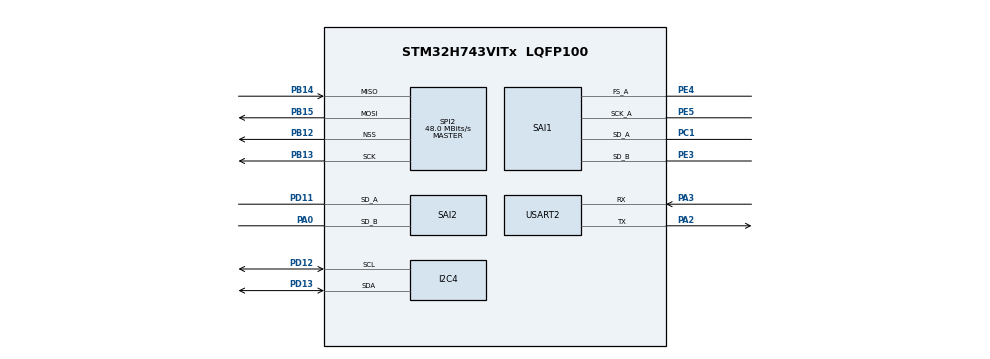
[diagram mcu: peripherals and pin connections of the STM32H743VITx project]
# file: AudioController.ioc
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CORTEX_M7.AccessPermission-Cortex_Memory_Protection_Unit_Region0_Settings=MPU_REGION_FULL_ACCESS
CORTEX_M7.BaseAddress-Cortex_Memory_Protection_Unit_Region0_Settings=0x24000000
CORTEX_M7.CPU_DCache=Enabled
CORTEX_M7.CPU_ICache=Enabled
CORTEX_M7.DisableExec-Cortex_Memory_Protection_Unit_Region0_Settings=MPU_INSTRUCTION_ACCESS_DISABLE
CORTEX_M7.Enable-Cortex_Memory_Protection_Unit_Region0_Settings=MPU_REGION_ENABLE
CORTEX_M7.IsBufferable-Cortex_Memory_Protection_Unit_Region0_Settings=MPU_ACCESS_BUFFERABLE
CORTEX_M7.IsShareable-Cortex_Memory_Protection_Unit_Region0_Settings=MPU_ACCESS_SHAREABLE
CORTEX_M7.MPU_Control=MPU_PRIVILEGED_DEFAULT
CORTEX_M7.Size-Cortex_Memory_Protection_Unit_Region0_Settings=MPU_REGION_SIZE_256KB
Dma.Request0=SAI2_A
Dma.Request1=SAI2_B
Dma.Request2=SAI1_A
Dma.Request3=SAI1_B
Dma.Request4=USART2_RX
Dma.Request5=USART2_TX
Dma.Request6=SPI2_RX
Dma.Request7=SPI2_TX
Dma.SAI1_A.2.Direction=DMA_PERIPH_TO_MEMORY
Dma.SAI1_A.2.EventEnable=DISABLE
Dma.SAI1_A.2.FIFOMode=DMA_FIFOMODE_DISABLE
Dma.SAI1_A.2.Instance=DMA1_Stream2
Dma.SAI1_A.2.MemDataAlignment=DMA_MDATAALIGN_HALFWORD
Dma.SAI1_A.2.MemInc=DMA_MINC_ENABLE
Dma.SAI1_A.2.Mode=DMA_CIRCULAR
Dma.SAI1_A.2.PeriphDataAlignment=DMA_PDATAALIGN_HALFWORD
Dma.SAI1_A.2.PeriphInc=DMA_PINC_DISABLE
Dma.SAI1_A.2.Polarity=HAL_DMAMUX_REQ_GEN_RISING
Dma.SAI1_A.2.Priority=DMA_PRIORITY_MEDIUM
Dma.SAI1_A.2.RequestNumber=1
Dma.SAI1_A.2.SignalID=NONE
Dma.SAI1_A.2.SyncEnable=DISABLE
Dma.SAI1_A.2.SyncPolarity=HAL_DMAMUX_SYNC_NO_EVENT
Dma.SAI1_A.2.SyncRequestNumber=1
Dma.SAI1_A.2.SyncSignalID=NONE
Dma.SAI1_B.3.Direction=DMA_MEMORY_TO_PERIPH
Dma.SAI1_B.3.EventEnable=DISABLE
Dma.SAI1_B.3.FIFOMode=DMA_FIFOMODE_DISABLE
Dma.SAI1_B.3.Instance=DMA1_Stream3
Dma.SAI1_B.3.MemDataAlignment=DMA_MDATAALIGN_HALFWORD
Dma.SAI1_B.3.MemInc=DMA_MINC_ENABLE
Dma.SAI1_B.3.Mode=DMA_CIRCULAR
Dma.SAI1_B.3.PeriphDataAlignment=DMA_PDATAALIGN_HALFWORD
Dma.SAI1_B.3.PeriphInc=DMA_PINC_DISABLE
Dma.SAI1_B.3.Polarity=HAL_DMAMUX_REQ_GEN_RISING
Dma.SAI1_B.3.Priority=DMA_PRIORITY_MEDIUM
Dma.SAI1_B.3.RequestNumber=1
Dma.SAI1_B.3.SignalID=NONE
Dma.SAI1_B.3.SyncEnable=DISABLE
Dma.SAI1_B.3.SyncPolarity=HAL_DMAMUX_SYNC_NO_EVENT
Dma.SAI1_B.3.SyncRequestNumber=1
Dma.SAI1_B.3.SyncSignalID=NONE
Dma.SAI2_A.0.Direction=DMA_PERIPH_TO_MEMORY
Dma.SAI2_A.0.EventEnable=DISABLE
Dma.SAI2_A.0.FIFOMode=DMA_FIFOMODE_DISABLE
Dma.SAI2_A.0.Instance=DMA1_Stream0
Dma.SAI2_A.0.MemDataAlignment=DMA_MDATAALIGN_HALFWORD
Dma.SAI2_A.0.MemInc=DMA_MINC_ENABLE
Dma.SAI2_A.0.Mode=DMA_CIRCULAR
Dma.SAI2_A.0.PeriphDataAlignment=DMA_PDATAALIGN_HALFWORD
Dma.SAI2_A.0.PeriphInc=DMA_PINC_DISABLE
Dma.SAI2_A.0.Polarity=HAL_DMAMUX_REQ_GEN_RISING
Dma.SAI2_A.0.Priority=DMA_PRIORITY_MEDIUM
Dma.SAI2_A.0.RequestNumber=1
Dma.SAI2_A.0.SignalID=NONE
Dma.SAI2_A.0.SyncEnable=DISABLE
Dma.SAI2_A.0.SyncPolarity=HAL_DMAMUX_SYNC_NO_EVENT
Dma.SAI2_A.0.SyncRequestNumber=1
Dma.SAI2_A.0.SyncSignalID=NONE
Dma.SAI2_B.1.Direction=DMA_MEMORY_TO_PERIPH
Dma.SAI2_B.1.EventEnable=DISABLE
Dma.SAI2_B.1.FIFOMode=DMA_FIFOMODE_DISABLE
Dma.SAI2_B.1.Instance=DMA1_Stream1
Dma.SAI2_B.1.MemDataAlignment=DMA_MDATAALIGN_HALFWORD
Dma.SAI2_B.1.MemInc=DMA_MINC_ENABLE
Dma.SAI2_B.1.Mode=DMA_CIRCULAR
Dma.SAI2_B.1.PeriphDataAlignment=DMA_PDATAALIGN_HALFWORD
Dma.SAI2_B.1.PeriphInc=DMA_PINC_DISABLE
Dma.SAI2_B.1.Polarity=HAL_DMAMUX_REQ_GEN_RISING
Dma.SAI2_B.1.Priority=DMA_PRIORITY_MEDIUM
Dma.SAI2_B.1.RequestNumber=1
Dma.SAI2_B.1.SignalID=NONE
Dma.SAI2_B.1.SyncEnable=DISABLE
Dma.SAI2_B.1.SyncPolarity=HAL_DMAMUX_SYNC_NO_EVENT
Dma.SAI2_B.1.SyncRequestNumber=1
Dma.SAI2_B.1.SyncSignalID=NONE
Dma.SPI2_RX.6.Direction=DMA_PERIPH_TO_MEMORY
Dma.SPI2_RX.6.EventEnable=DISABLE
Dma.SPI2_RX.6.FIFOMode=DMA_FIFOMODE_DISABLE
Dma.SPI2_RX.6.Instance=DMA1_Stream6
Dma.SPI2_RX.6.MemDataAlignment=DMA_MDATAALIGN_HALFWORD
Dma.SPI2_RX.6.MemInc=DMA_MINC_ENABLE
Dma.SPI2_RX.6.Mode=DMA_NORMAL
Dma.SPI2_RX.6.PeriphDataAlignment=DMA_PDATAALIGN_HALFWORD
Dma.SPI2_RX.6.PeriphInc=DMA_PINC_DISABLE
Dma.SPI2_RX.6.Polarity=HAL_DMAMUX_REQ_GEN_RISING
Dma.SPI2_RX.6.Priority=DMA_PRIORITY_LOW
Dma.SPI2_RX.6.RequestNumber=1
Dma.SPI2_RX.6.SignalID=NONE
Dma.SPI2_RX.6.SyncEnable=DISABLE
Dma.SPI2_RX.6.SyncPolarity=HAL_DMAMUX_SYNC_NO_EVENT
Dma.SPI2_RX.6.SyncRequestNumber=1
Dma.SPI2_RX.6.SyncSignalID=NONE
Dma.SPI2_TX.7.Direction=DMA_MEMORY_TO_PERIPH
Dma.SPI2_TX.7.EventEnable=DISABLE
Dma.SPI2_TX.7.FIFOMode=DMA_FIFOMODE_DISABLE
Dma.SPI2_TX.7.Instance=DMA1_Stream7
Dma.SPI2_TX.7.MemDataAlignment=DMA_MDATAALIGN_HALFWORD
Dma.SPI2_TX.7.MemInc=DMA_MINC_ENABLE
Dma.SPI2_TX.7.Mode=DMA_NORMAL
Dma.SPI2_TX.7.PeriphDataAlignment=DMA_PDATAALIGN_HALFWORD
Dma.SPI2_TX.7.PeriphInc=DMA_PINC_DISABLE
Dma.SPI2_TX.7.Polarity=HAL_DMAMUX_REQ_GEN_RISING
Dma.SPI2_TX.7.Priority=DMA_PRIORITY_LOW
Dma.SPI2_TX.7.RequestNumber=1
Dma.SPI2_TX.7.SignalID=NONE
Dma.SPI2_TX.7.SyncEnable=DISABLE
Dma.SPI2_TX.7.SyncPolarity=HAL_DMAMUX_SYNC_NO_EVENT
Dma.SPI2_TX.7.SyncRequestNumber=1
Dma.SPI2_TX.7.SyncSignalID=NONE
Dma.USART2_RX.4.Direction=DMA_PERIPH_TO_MEMORY
Dma.USART2_RX.4.EventEnable=DISABLE
Dma.USART2_RX.4.FIFOMode=DMA_FIFOMODE_DISABLE
Dma.USART2_RX.4.Instance=DMA1_Stream4
Dma.USART2_RX.4.MemDataAlignment=DMA_MDATAALIGN_BYTE
Dma.USART2_RX.4.MemInc=DMA_MINC_ENABLE
Dma.USART2_RX.4.Mode=DMA_CIRCULAR
Dma.USART2_RX.4.PeriphDataAlignment=DMA_PDATAALIGN_BYTE
Dma.USART2_RX.4.PeriphInc=DMA_PINC_DISABLE
Dma.USART2_RX.4.Polarity=HAL_DMAMUX_REQ_GEN_RISING
Dma.USART2_RX.4.Priority=DMA_PRIORITY_LOW
Dma.USART2_RX.4.RequestNumber=1
Dma.USART2_RX.4.SignalID=NONE
Dma.USART2_RX.4.SyncEnable=DISABLE
Dma.USART2_RX.4.SyncPolarity=HAL_DMAMUX_SYNC_NO_EVENT
Dma.USART2_RX.4.SyncRequestNumber=1
Dma.USART2_RX.4.SyncSignalID=NONE
Dma.USART2_TX.5.Direction=DMA_MEMORY_TO_PERIPH
Dma.USART2_TX.5.EventEnable=DISABLE
Dma.USART2_TX.5.FIFOMode=DMA_FIFOMODE_DISABLE
Dma.USART2_TX.5.Instance=DMA1_Stream5
Dma.USART2_TX.5.MemDataAlignment=DMA_MDATAALIGN_BYTE
Dma.USART2_TX.5.MemInc=DMA_MINC_ENABLE
Dma.USART2_TX.5.Mode=DMA_NORMAL
Dma.USART2_TX.5.PeriphDataAlignment=DMA_PDATAALIGN_BYTE
Dma.USART2_TX.5.PeriphInc=DMA_PINC_DISABLE
Dma.USART2_TX.5.Polarity=HAL_DMAMUX_REQ_GEN_RISING
Dma.USART2_TX.5.Priority=DMA_PRIORITY_LOW
Dma.USART2_TX.5.RequestNumber=1
Dma.USART2_TX.5.SignalID=NONE
Dma.USART2_TX.5.SyncEnable=DISABLE
Dma.USART2_TX.5.SyncPolarity=HAL_DMAMUX_SYNC_NO_EVENT
Dma.USART2_TX.5.SyncRequestNumber=1
Dma.USART2_TX.5.SyncSignalID=NONE
I2C4.Timing=0x00000E14
Mcu.Family=STM32H7
Mcu.Name=STM32H743VITx
Mcu.Package=LQFP100
NVIC.DMA1_Stream0_IRQn=true\:0\:0\:false\:false\:true\:false\:true\:true
NVIC.DMA1_Stream1_IRQn=true\:0\:0\:false\:false\:true\:false\:true\:true
NVIC.DMA1_Stream2_IRQn=true\:0\:0\:false\:false\:true\:false\:true\:true
NVIC.DMA1_Stream3_IRQn=true\:0\:0\:false\:false\:true\:false\:true\:true
NVIC.DMA1_Stream4_IRQn=true\:0\:0\:false\:false\:true\:false\:true\:true
NVIC.DMA1_Stream5_IRQn=true\:0\:0\:false\:false\:true\:false\:true\:true
NVIC.DMA1_Stream6_IRQn=true\:0\:0\:false\:false\:true\:false\:true\:true
NVIC.DMA1_Stream7_IRQn=true\:0\:0\:false\:false\:true\:false\:true\:true
NVIC.PriorityGroup=NVIC_PRIORITYGROUP_4
NVIC.SAI1_IRQn=true\:0\:0\:false\:false\:true\:true\:true\:true
NVIC.SAI2_IRQn=true\:0\:0\:false\:false\:true\:true\:true\:true
NVIC.SPI2_IRQn=true\:0\:0\:false\:false\:true\:true\:true\:true
NVIC.USART2_IRQn=true\:0\:0\:false\:false\:true\:true\:true\:true
PA0.GPIO_Speed=GPIO_SPEED_FREQ_VERY_HIGH
PA0.Mode=SAI_B_SyncSlave
PA0.Signal=SAI2_SD_B
PA13\ (JTMS/SWDIO).Mode=Trace_Asynchronous_SW
PA13\ (JTMS/SWDIO).Signal=DEBUG_JTMS-SWDIO
PA14\ (JTCK/SWCLK).Mode=Trace_Asynchronous_SW
PA14\ (JTCK/SWCLK).Signal=DEBUG_JTCK-SWCLK
PA2.Mode=Asynchronous
PA2.Signal=USART2_TX
PA3.Mode=Asynchronous
PA3.Signal=USART2_RX
PB12.GPIO_Speed=GPIO_SPEED_FREQ_VERY_HIGH
PB12.Mode=NSS_Signal_Hard_Output
PB12.Signal=SPI2_NSS
PB13.GPIO_Speed=GPIO_SPEED_FREQ_VERY_HIGH
PB13.Mode=Full_Duplex_Master
PB13.Signal=SPI2_SCK
PB14.GPIO_Speed=GPIO_SPEED_FREQ_VERY_HIGH
PB14.Mode=Full_Duplex_Master
PB14.Signal=SPI2_MISO
PB15.GPIO_Speed=GPIO_SPEED_FREQ_VERY_HIGH
PB15.Mode=Full_Duplex_Master
PB15.Signal=SPI2_MOSI
PB3\ (JTDO/TRACESWO).Mode=Trace_Asynchronous_SW
PB3\ (JTDO/TRACESWO).Signal=DEBUG_JTDO-SWO
PC1.GPIO_Speed=GPIO_SPEED_FREQ_VERY_HIGH
PC1.Mode=SAI_A_AsyncSlave
PC1.Signal=SAI1_SD_A
PD11.GPIO_Speed=GPIO_SPEED_FREQ_VERY_HIGH
PD11.Mode=SAI_A_SyncSlave
PD11.Signal=SAI2_SD_A
PD12.GPIO_Speed=GPIO_SPEED_FREQ_HIGH
PD12.Mode=I2C
PD12.Signal=I2C4_SCL
PD13.GPIO_Speed=GPIO_SPEED_FREQ_HIGH
PD13.Mode=I2C
PD13.Signal=I2C4_SDA
PE3.GPIO_Speed=GPIO_SPEED_FREQ_VERY_HIGH
PE3.Mode=SAI_B_SyncSlave
PE3.Signal=SAI1_SD_B
PE4.GPIO_Speed=GPIO_SPEED_FREQ_VERY_HIGH
PE4.Mode=SAI_A_AsyncSlave
PE4.Signal=SAI1_FS_A
PE5.GPIO_Speed=GPIO_SPEED_FREQ_VERY_HIGH
PE5.Mode=SAI_A_AsyncSlave
PE5.Signal=SAI1_SCK_A
PH0-OSC_IN\ (PH0).Mode=HSE-External-Oscillator
PH0-OSC_IN\ (PH0).Signal=RCC_OSC_IN
PH1-OSC_OUT\ (PH1).Mode=HSE-External-Oscillator
PH1-OSC_OUT\ (PH1).Signal=RCC_OSC_OUT
ProjectManager.HeapSize=0x1600
ProjectManager.StackSize=0x2400
ProjectManager.TargetToolchain=STM32CubeIDE
RCC.ADCFreq_Value=12288000
RCC.APB1Freq_Value=120000000
RCC.APB2Freq_Value=120000000
RCC.APB3Freq_Value=120000000
RCC.APB4Freq_Value=120000000
RCC.CortexFreq_Value=480000000
RCC.D1PPRE=RCC_APB3_DIV2
RCC.D2PPRE1=RCC_APB1_DIV2
RCC.D2PPRE2=RCC_APB2_DIV2
RCC.D3PPRE=RCC_APB4_DIV2
RCC.DIVM1=3
RCC.DIVM2=5
RCC.DIVM3=8
RCC.DIVN1=120
RCC.DIVN2=64
RCC.DIVN3=96
RCC.DIVP2=25
RCC.DIVP3=3
RCC.DIVQ3=4
RCC.DIVR3=3
RCC.EnbaleCSS=true
RCC.HCLKFreq_Value=240000000
RCC.HPRE=RCC_HCLK_DIV2
RCC.HSE_VALUE=24000000
RCC.I2C4CLockSelection=RCC_I2C4CLKSOURCE_CSI
RCC.PLLSourceVirtual=RCC_PLLSOURCE_HSE
RCC.SAI1CLockSelection=RCC_SAI1CLKSOURCE_PLL2
RCC.SAI23CLockSelection=RCC_SAI23CLKSOURCE_PLL2
RCC.SPI123CLockSelection=RCC_SPI123CLKSOURCE_PLL3
RCC.SYSCLKFreq_VALUE=480000000
RCC.SYSCLKSource=RCC_SYSCLKSOURCE_PLLCLK
RCC.USBFreq_Value=480000000
SAI1.AudioMode-SAI_B_SyncSlave=SAI_MODESLAVE_TX
SAI1.BasicDataSize-SAI_A_AsyncSlave=SAI_PROTOCOL_DATASIZE_16BITEXTENDED
SAI1.BasicDataSize-SAI_B_SyncSlave=SAI_PROTOCOL_DATASIZE_16BITEXTENDED
SAI1.InitProtocol-SAI_A_AsyncSlave=Enable
SAI1.InitProtocol-SAI_B_SyncSlave=Enable
SAI1.Instance-SAI_A_AsyncSlave=SAI$Index_Block_A
SAI1.Instance-SAI_B_SyncSlave=SAI$Index_Block_B
SAI1.SynchroExt=SAI_SYNCEXT_OUTBLOCKA_ENABLE
SAI1.VirtualMode-SAI_A_AsyncSlave=VM_SLAVE
SAI1.VirtualMode-SAI_B_SyncSlave=VM_SLAVE
SAI1.VirtualProtocol-SAI_A_BASIC=VM_BASIC_PROTOCOL
SAI1.VirtualProtocol-SAI_B_BASIC=VM_BASIC_PROTOCOL
SAI2.AudioMode-SAI_B_SyncSlave=SAI_MODESLAVE_TX
SAI2.BasicDataSize-SAI_A_SyncSlave=SAI_PROTOCOL_DATASIZE_16BITEXTENDED
SAI2.BasicDataSize-SAI_B_SyncSlave=SAI_PROTOCOL_DATASIZE_16BITEXTENDED
SAI2.InitProtocol-SAI_A_SyncSlave=Enable
SAI2.InitProtocol-SAI_B_SyncSlave=Enable
SAI2.Instance-SAI_A_SyncSlave=SAI$Index_Block_A
SAI2.Instance-SAI_B_SyncSlave=SAI$Index_Block_B
SAI2.Synchro_A=SAI_SYNCHRONOUS_EXT_SAI1
SAI2.Synchro_B=SAI_SYNCHRONOUS_EXT_SAI1
SAI2.VirtualMode-SAI_A_SyncSlave=VM_SLAVE
SAI2.VirtualMode-SAI_B_SyncSlave=VM_SLAVE
SAI2.VirtualProtocol-SAI_A_BASIC=VM_BASIC_PROTOCOL
SAI2.VirtualProtocol-SAI_B_BASIC=VM_BASIC_PROTOCOL
SPI2.BaudRatePrescaler=SPI_BAUDRATEPRESCALER_2
SPI2.CalculateBaudRate=48.0 MBits/s
SPI2.DataSize=SPI_DATASIZE_16BIT
SPI2.Direction=SPI_DIRECTION_2LINES
SPI2.Mode=SPI_MODE_MASTER
SPI2.VirtualNSS=VM_NSSHARD
SPI2.VirtualType=VM_MASTER
USART2.AutoBaudRateEnableParam=UART_ADVFEATURE_AUTOBAUDRATE_DISABLE
USART2.OverSampling=UART_OVERSAMPLING_16
USART2.Parity=PARITY_NONE
USART2.RXFIFOThreshold=RXFIFO_THRESHOLD_HALFFULL
USART2.RxPinLevelInvertParam=ADVFEATURE_RXINV_DISABLE
USART2.TXFIFOThreshold=TXFIFO_THRESHOLD_HALFFULL
USART2.TxPinLevelInvertParam=ADVFEATURE_TXINV_DISABLE
USART2.VirtualMode-Asynchronous=VM_ASYNC
USART2.WordLength=WORDLENGTH_8B
VP_SAI1_VP_$IpInstance_SAIA_SAI_BASIC.Mode=SAI_A_BASIC
VP_SAI1_VP_$IpInstance_SAIB_SAI_BASIC.Mode=SAI_B_BASIC
VP_SAI1_VP_$IpInstance_SYNCHRO_EXTERNAL.Mode=SynchroExternal
VP_SAI2_VP_$IpInstance_SAIA_SAI_BASIC.Mode=SAI_A_BASIC
VP_SAI2_VP_$IpInstance_SAIB_SAI_BASIC.Mode=SAI_B_BASIC
board=custom

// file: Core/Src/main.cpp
/* USER CODE BEGIN Header */
/**
 ******************************************************************************
 * @file           : main.c
 * @brief          : Main program body
 ******************************************************************************
 * @attention
 *
 * Copyright (c) 2023 STMicroelectronics.
 * All rights reserved.
 *
 * This software is licensed under terms that can be found in the LICENSE file
 * in the root directory of this software component.
 * If no LICENSE file comes with this software, it is provided AS-IS.
 *
 ******************************************************************************
 */
/* USER CODE END Header */
#include "main.h"
#include "dma.h"
#include "i2c.h"
#include "sai.h"
#include "spi.h"
#include "usart.h"
#include "gpio.h"

/* USER CODE BEGIN Includes */
////////////////////////////////////////////////
////// S A I    O R D E R //////////////////////
////////////////////////////////////////////////
////////////////////////////////////////////////
// ramd1_dma - i fixed linker script
//
/////////////////////////////////////////////////
#include "Handy.h"
#include "../../Drivers/HW/wm8731.h"
#include "../../HW/GUIadapter.h"
#include "../../Modules/AudioSys.hpp"

/* USER CODE END Includes */

void SystemClock_Config(void);
void PeriphCommonClock_Config(void);
static void MPU_Config(void);

int main(void)
{

  /* MPU Configuration--------------------------------------------------------*/
  MPU_Config();

  /* Enable I-Cache---------------------------------------------------------*/
  SCB_EnableICache();

  /* Enable D-Cache---------------------------------------------------------*/
  SCB_EnableDCache();

  /* MCU Configuration--------------------------------------------------------*/

  /* Reset of all peripherals, Initializes the Flash interface and the Systick. */
  HAL_Init();

  /* Configure the system clock */
  SystemClock_Config();

/* Configure the peripherals common clocks */
  PeriphCommonClock_Config();

  /* Initialize all configured peripherals */
  MX_GPIO_Init();
  MX_DMA_Init();
  MX_SAI1_Init();
  MX_SAI2_Init();
  MX_I2C4_Init();
  MX_USART2_UART_Init();
  MX_SPI2_Init();
  /* USER CODE BEGIN 2 */

	CodecPowerUp(CODEC_ADDRESS_1);
	SetHPGain(-8, CODEC_ADDRESS_1);

	CodecPowerUp(CODEC_ADDRESS_0);
	SetHPGain(-8, CODEC_ADDRESS_0);

	saiAdapter_Init(&sai2adapter, HW_SAI2);
	saiAdapter_Init(&sai1adapter, HW_SAI1);

	audioSystem.includeModules();
	guiAdapter_Init(&guiadapter);

  /* USER CODE END 2 */

  /* Infinite loop */
  /* USER CODE BEGIN WHILE */
	while (1) {
		//audioSystem.updateParams();
		audioSystem.update();
    /* USER CODE END WHILE */

	}
}

void SystemClock_Config(void)
{
  RCC_OscInitTypeDef RCC_OscInitStruct = {0};
  RCC_ClkInitTypeDef RCC_ClkInitStruct = {0};

  /** Supply configuration update enable
  */
  HAL_PWREx_ConfigSupply(PWR_LDO_SUPPLY);

  /** Configure the main internal regulator output voltage
  */
  __HAL_PWR_VOLTAGESCALING_CONFIG(PWR_REGULATOR_VOLTAGE_SCALE1);

  while(!__HAL_PWR_GET_FLAG(PWR_FLAG_VOSRDY)) {}

  __HAL_RCC_SYSCFG_CLK_ENABLE();
  __HAL_PWR_VOLTAGESCALING_CONFIG(PWR_REGULATOR_VOLTAGE_SCALE0);

  while(!__HAL_PWR_GET_FLAG(PWR_FLAG_VOSRDY)) {}

  /** Macro to configure the PLL clock source
  */
  __HAL_RCC_PLL_PLLSOURCE_CONFIG(RCC_PLLSOURCE_HSE);

  /** Initializes the RCC Oscillators according to the specified parameters
  * in the RCC_OscInitTypeDef structure.
  */
  RCC_OscInitStruct.OscillatorType = RCC_OSCILLATORTYPE_CSI|RCC_OSCILLATORTYPE_HSE;
  RCC_OscInitStruct.HSEState = RCC_HSE_ON;
  RCC_OscInitStruct.CSIState = RCC_CSI_ON;
  RCC_OscInitStruct.CSICalibrationValue = RCC_CSICALIBRATION_DEFAULT;
  RCC_OscInitStruct.PLL.PLLState = RCC_PLL_ON;
  RCC_OscInitStruct.PLL.PLLSource = RCC_PLLSOURCE_HSE;
  RCC_OscInitStruct.PLL.PLLM = 3;
  RCC_OscInitStruct.PLL.PLLN = 120;
  RCC_OscInitStruct.PLL.PLLP = 2;
  RCC_OscInitStruct.PLL.PLLQ = 2;
  RCC_OscInitStruct.PLL.PLLR = 2;
  RCC_OscInitStruct.PLL.PLLRGE = RCC_PLL1VCIRANGE_3;
  RCC_OscInitStruct.PLL.PLLVCOSEL = RCC_PLL1VCOWIDE;
  RCC_OscInitStruct.PLL.PLLFRACN = 0;
  if (HAL_RCC_OscConfig(&RCC_OscInitStruct) != HAL_OK)
  {
    Error_Handler();
  }

  /** Initializes the CPU, AHB and APB buses clocks
  */
  RCC_ClkInitStruct.ClockType = RCC_CLOCKTYPE_HCLK|RCC_CLOCKTYPE_SYSCLK
                              |RCC_CLOCKTYPE_PCLK1|RCC_CLOCKTYPE_PCLK2
                              |RCC_CLOCKTYPE_D3PCLK1|RCC_CLOCKTYPE_D1PCLK1;
  RCC_ClkInitStruct.SYSCLKSource = RCC_SYSCLKSOURCE_PLLCLK;
  RCC_ClkInitStruct.SYSCLKDivider = RCC_SYSCLK_DIV1;
  RCC_ClkInitStruct.AHBCLKDivider = RCC_HCLK_DIV2;
  RCC_ClkInitStruct.APB3CLKDivider = RCC_APB3_DIV2;
  RCC_ClkInitStruct.APB1CLKDivider = RCC_APB1_DIV2;
  RCC_ClkInitStruct.APB2CLKDivider = RCC_APB2_DIV2;
  RCC_ClkInitStruct.APB4CLKDivider = RCC_APB4_DIV2;

  if (HAL_RCC_ClockConfig(&RCC_ClkInitStruct, FLASH_LATENCY_4) != HAL_OK)
  {
    Error_Handler();
  }

  /** Enables the Clock Security System
  */
  HAL_RCC_EnableCSS();
}

void PeriphCommonClock_Config(void)
{
  RCC_PeriphCLKInitTypeDef PeriphClkInitStruct = {0};

  /** Initializes the peripherals clock
  */
  PeriphClkInitStruct.PeriphClockSelection = RCC_PERIPHCLK_SAI1|RCC_PERIPHCLK_SAI2;
  PeriphClkInitStruct.PLL2.PLL2M = 5;
  PeriphClkInitStruct.PLL2.PLL2N = 64;
  PeriphClkInitStruct.PLL2.PLL2P = 25;
  PeriphClkInitStruct.PLL2.PLL2Q = 2;
  PeriphClkInitStruct.PLL2.PLL2R = 2;
  PeriphClkInitStruct.PLL2.PLL2RGE = RCC_PLL2VCIRANGE_2;
  PeriphClkInitStruct.PLL2.PLL2VCOSEL = RCC_PLL2VCOWIDE;
  PeriphClkInitStruct.PLL2.PLL2FRACN = 0;
  PeriphClkInitStruct.Sai1ClockSelection = RCC_SAI1CLKSOURCE_PLL2;
  PeriphClkInitStruct.Sai23ClockSelection = RCC_SAI23CLKSOURCE_PLL2;
  if (HAL_RCCEx_PeriphCLKConfig(&PeriphClkInitStruct) != HAL_OK)
  {
    Error_Handler();
  }
}

/* MPU Configuration */

void MPU_Config(void)
{
  MPU_Region_InitTypeDef MPU_InitStruct = {0};

  /* Disables the MPU */
  HAL_MPU_Disable();

  /** Initializes and configures the Region and the memory to be protected
  */
  MPU_InitStruct.Enable = MPU_REGION_ENABLE;
  MPU_InitStruct.Number = MPU_REGION_NUMBER0;
  MPU_InitStruct.BaseAddress = 0x24000000;
  MPU_InitStruct.Size = MPU_REGION_SIZE_256KB;
  MPU_InitStruct.SubRegionDisable = 0x0;
  MPU_InitStruct.TypeExtField = MPU_TEX_LEVEL0;
  MPU_InitStruct.AccessPermission = MPU_REGION_FULL_ACCESS;
  MPU_InitStruct.DisableExec = MPU_INSTRUCTION_ACCESS_DISABLE;
  MPU_InitStruct.IsShareable = MPU_ACCESS_SHAREABLE;
  MPU_InitStruct.IsCacheable = MPU_ACCESS_NOT_CACHEABLE;
  MPU_InitStruct.IsBufferable = MPU_ACCESS_BUFFERABLE;

  HAL_MPU_ConfigRegion(&MPU_InitStruct);
  /* Enables the MPU */
  HAL_MPU_Enable(MPU_PRIVILEGED_DEFAULT);

}

void Error_Handler(void)
{
	__disable_irq();
	while (1) {
	}
}
